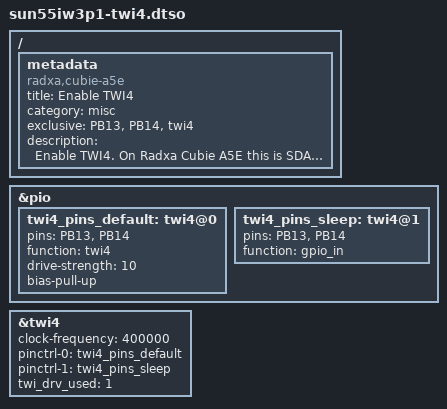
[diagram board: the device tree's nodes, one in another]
/dts-v1/;
/plugin/;

/ {
	metadata {
		title = "Enable TWI4";
		compatible = "radxa,cubie-a5e";
		category = "misc";
		exclusive = "PB13", "PB14", "twi4";
		description = "Enable TWI4.
On Radxa Cubie A5E this is SDA pin 21 & SCL pin 19.";
    };
};

&pio {
	twi4_pins_default: twi4@0 {
		pins = "PB13", "PB14";
		function = "twi4";
		drive-strength = <10>;
		bias-pull-up;
	};

	twi4_pins_sleep: twi4@1 {
		pins = "PB13", "PB14";
		function = "gpio_in";
	};
};

&twi4 {
	clock-frequency = <400000>;
	pinctrl-0 = <&twi4_pins_default>;
	pinctrl-1 = <&twi4_pins_sleep>;
	pinctrl-names = "default", "sleep";
	/* For stability and backwards compatibility, we recommend setting ‘twi_drv_used’ to 1 */
	twi_drv_used = <1>;
	status = "okay";
};
